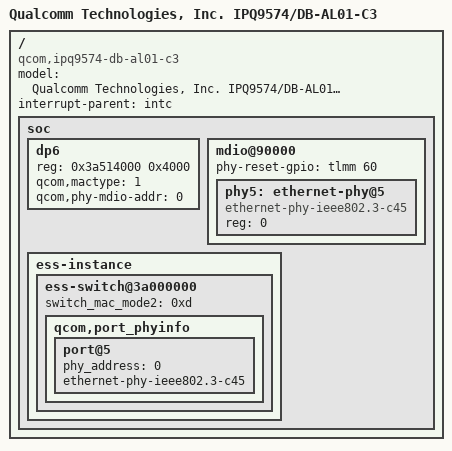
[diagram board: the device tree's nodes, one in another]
// SPDX-License-Identifier: (GPL-2.0+ OR BSD-3-Clause)
/*
 * IPQ9574 DB-AL01-C3 board device tree source
 *
 * Copyright (c) 2020-2021 The Linux Foundation. All rights reserved.
 */

/dts-v1/;

#include "ipq9574-db-al01-c1.dts"

/ {
	#address-cells = <0x2>;
	#size-cells = <0x2>;
	model = "Qualcomm Technologies, Inc. IPQ9574/DB-AL01-C3";
	compatible = "qcom,ipq9574-db-al01-c3", "qcom,ipq9574-db-al01", "qcom,ipq9574";
	interrupt-parent = <&intc>;

	soc {
		dp6 {
			reg = <0x3a514000 0x4000>;
			qcom,mactype = <1>;
			qcom,phy-mdio-addr = <0>;
                };

		mdio@90000 {
			/*gpio60 is for malibu reset*/
			phy-reset-gpio = <&tlmm 60 0>;
			phy5: ethernet-phy@5 {
				compatible ="ethernet-phy-ieee802.3-c45";
				reg = <0>;
                        };
		};

		ess-instance {
			ess-switch@3a000000 {
				switch_mac_mode2 = <0xd>; /* mac mode for uniphy instance2*/
				qcom,port_phyinfo {
					port@5 {
						phy_address = <0>;
						ethernet-phy-ieee802.3-c45;
						/delete-property/port_mac_sel;
					};
				};
			};
		};
		/delete-node/ nss-macsec1;
	};
};
